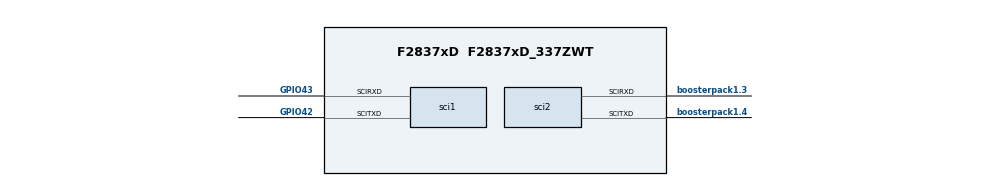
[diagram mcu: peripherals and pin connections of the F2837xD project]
/**
 * @cliArgs --board "/boards/LAUNCHXL_F28379D" --device "F2837xD" --part "F2837xD_337ZWT" --package "F2837xD_337ZWT" --context "CPU1" --product "C2000WARE@5.04.00.00"
 * @versions {"tool":"1.22.0+3893"}
 */

/**
 * Import the modules used in this configuration.
 */
const led       = scripting.addModule("/driverlib/board_components/led", {}, false);
const led1      = led.addInstance();
const cputimer  = scripting.addModule("/driverlib/cputimer.js", {}, false);
const cputimer1 = cputimer.addInstance();
const sci       = scripting.addModule("/driverlib/sci.js", {}, false);
const sci1      = sci.addInstance();
const sci2      = sci.addInstance();

/**
 * Write custom configuration values to the imported modules.
 */
led1.$name     = "myBoardLED0";
led1.$hardware = system.deviceData.board.components.LED5;

cputimer1.$name                    = "myCPUTIMER0";
cputimer1.timerPrescaler           = 1;
cputimer1.enableInterrupt          = true;
cputimer1.registerInterrupts       = true;
cputimer1.timerPeriod              = 200000000;
cputimer1.timerInt.enableInterrupt = true;

sci1.$name                      = "mySCIA";
sci1.enabledFIFOInterrupts      = ["SCI_INT_RXFF"];
sci1.selectRegisteredInterrupts = ["registerRxInt"];
sci1.rxFifo                     = "SCI_FIFO_RX1";
sci1.baudRates                  = 9600;
sci1.sci.$assign                = "SCIA";
sci1.sci.scirxdPin.$assign      = "GPIO43";
sci1.sci.scitxdPin.$assign      = "GPIO42";
sci1.rxQual.$name               = "myGPIOQUAL0";
sci1.txQual.$name               = "myGPIOQUAL1";
sci1.sciRXInt.enableInterrupt   = true;

sci2.$name                 = "mySCI1";
sci2.baudRates             = 9600;
sci2.useInterrupts         = false;
sci2.sci.$assign           = "SCIB";
sci2.sci.scirxdPin.$assign = "boosterpack1.3";
sci2.sci.scitxdPin.$assign = "boosterpack1.4";
sci2.rxQual.$name          = "myGPIOQUAL2";
sci2.txQual.$name          = "myGPIOQUAL3";

/**
 * Pinmux solution for unlocked pins/peripherals. This ensures that minor changes to the automatic solver in a future
 * version of the tool will not impact the pinmux you originally saw.  These lines can be completely deleted in order to
 * re-solve from scratch.
 */
led1.gpio.gpioPin.$suggestSolution = "GPIO34";
